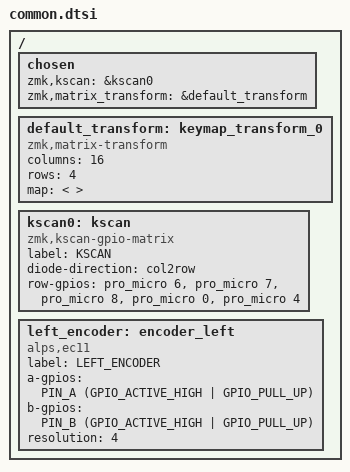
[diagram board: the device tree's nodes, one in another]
#include <dt-bindings/zmk/matrix_transform.h>

/ {
    chosen {
        zmk,kscan = &kscan0;
        zmk,matrix_transform = &default_transform;
    };

    default_transform: keymap_transform_0 {
        compatible = "zmk,matrix-transform";
        columns = <16>;
        rows = <4>;
// todo map
        map = <
//todo map
        >;
    };

    kscan0: kscan {
        compatible = "zmk,kscan-gpio-matrix";
        label = "KSCAN";

        diode-direction = "col2row";
        row-gpios
            = <&pro_micro 6 (GPIO_ACTIVE_HIGH | GPIO_PULL_DOWN)> // Row A from the schematic file
            , <&pro_micro 7 (GPIO_ACTIVE_HIGH | GPIO_PULL_DOWN)> // Row B from the schematic file
            , <&pro_micro 8 (GPIO_ACTIVE_HIGH | GPIO_PULL_DOWN)> // Row C from the schematic file
            , <&pro_micro 0 (GPIO_ACTIVE_HIGH | GPIO_PULL_DOWN)> // Row D from the schematic file
            , <&pro_micro 4 (GPIO_ACTIVE_HIGH | GPIO_PULL_DOWN)> // Row E from the schematic file
            ;

    };

    left_encoder: encoder_left {
        compatible = "alps,ec11";
        label = "LEFT_ENCODER";
        a-gpios = <PIN_A (GPIO_ACTIVE_HIGH | GPIO_PULL_UP)>;
        b-gpios = <PIN_B (GPIO_ACTIVE_HIGH | GPIO_PULL_UP)>;
        resolution = <4>;
    };
    
};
